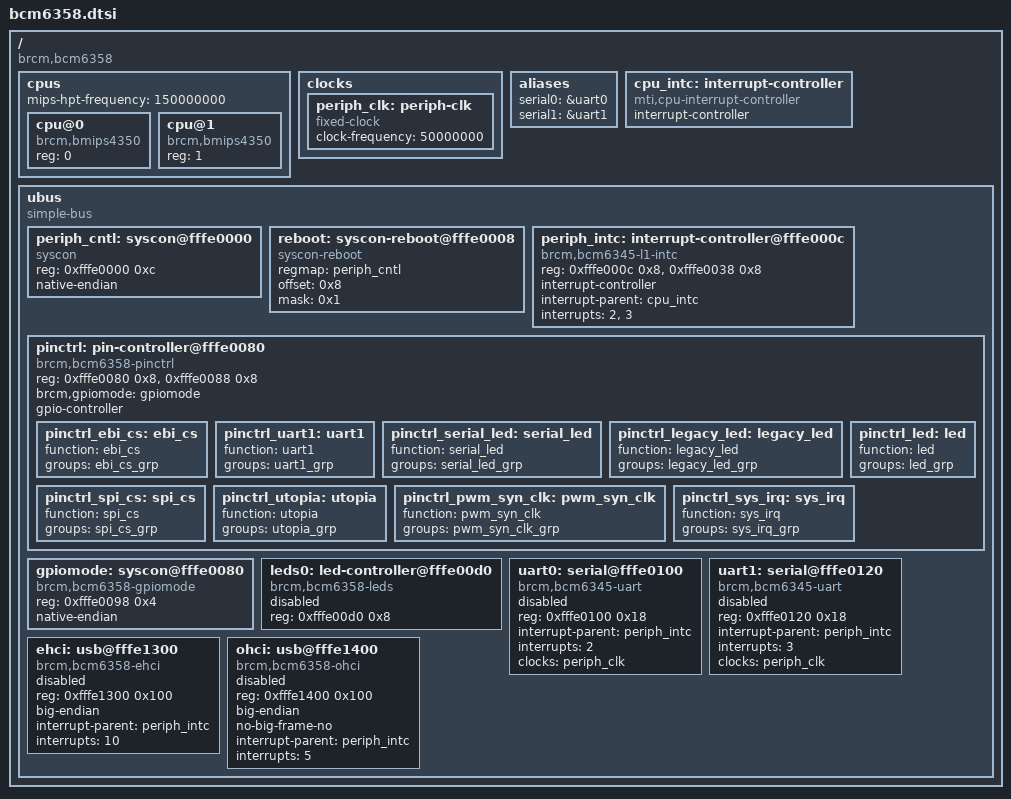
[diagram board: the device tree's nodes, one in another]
/ {
	#address-cells = <1>;
	#size-cells = <1>;
	compatible = "brcm,bcm6358";

	cpus {
		#address-cells = <1>;
		#size-cells = <0>;

		mips-hpt-frequency = <150000000>;

		cpu@0 {
			compatible = "brcm,bmips4350";
			device_type = "cpu";
			reg = <0>;
		};

		cpu@1 {
			compatible = "brcm,bmips4350";
			device_type = "cpu";
			reg = <1>;
		};
	};

	clocks {
		periph_clk: periph-clk {
			compatible = "fixed-clock";
			#clock-cells = <0>;
			clock-frequency = <50000000>;
		};
	};

	aliases {
		serial0 = &uart0;
		serial1 = &uart1;
	};

	cpu_intc: interrupt-controller {
		#address-cells = <0>;
		compatible = "mti,cpu-interrupt-controller";

		interrupt-controller;
		#interrupt-cells = <1>;
	};

	ubus {
		#address-cells = <1>;
		#size-cells = <1>;

		compatible = "simple-bus";
		ranges;

		periph_cntl: syscon@fffe0000 {
			compatible = "syscon";
			reg = <0xfffe0000 0xc>;
			native-endian;
		};

		reboot: syscon-reboot@fffe0008 {
			compatible = "syscon-reboot";
			regmap = <&periph_cntl>;
			offset = <0x8>;
			mask = <0x1>;
		};

		periph_intc: interrupt-controller@fffe000c {
			compatible = "brcm,bcm6345-l1-intc";
			reg = <0xfffe000c 0x8>,
			      <0xfffe0038 0x8>;

			interrupt-controller;
			#interrupt-cells = <1>;

			interrupt-parent = <&cpu_intc>;
			interrupts = <2>, <3>;
		};

		pinctrl: pin-controller@fffe0080 {
			compatible = "brcm,bcm6358-pinctrl";
			reg = <0xfffe0080 0x8>,
			      <0xfffe0088 0x8>;
			reg-names = "dirout", "dat";
			brcm,gpiomode = <&gpiomode>;

			gpio-controller;
			#gpio-cells = <2>;

			pinctrl_ebi_cs: ebi_cs {
				function = "ebi_cs";
				groups = "ebi_cs_grp";
			};

			pinctrl_uart1: uart1 {
				function = "uart1";
				groups = "uart1_grp";
			};

			pinctrl_serial_led: serial_led {
				function = "serial_led";
				groups = "serial_led_grp";
			};

			pinctrl_legacy_led: legacy_led {
				function = "legacy_led";
				groups = "legacy_led_grp";
			};

			pinctrl_led: led {
				function = "led";
				groups = "led_grp";
			};

			pinctrl_spi_cs: spi_cs {
				function = "spi_cs";
				groups = "spi_cs_grp";
			};

			pinctrl_utopia: utopia {
				function = "utopia";
				groups = "utopia_grp";
			};

			pinctrl_pwm_syn_clk: pwm_syn_clk {
				function = "pwm_syn_clk";
				groups = "pwm_syn_clk_grp";
			};

			pinctrl_sys_irq: sys_irq {
				function = "sys_irq";
				groups = "sys_irq_grp";
			};
		};

		gpiomode: syscon@fffe0080 {
			compatible = "brcm,bcm6358-gpiomode", "syscon";

			reg = <0xfffe0098 0x4>;
			native-endian;
		};

		leds0: led-controller@fffe00d0 {
			#address-cells = <1>;
			#size-cells = <0>;
			compatible = "brcm,bcm6358-leds";
			reg = <0xfffe00d0 0x8>;

			status = "disabled";
		};

		uart0: serial@fffe0100 {
			compatible = "brcm,bcm6345-uart";
			reg = <0xfffe0100 0x18>;

			interrupt-parent = <&periph_intc>;
			interrupts = <2>;

			clocks = <&periph_clk>;

			status = "disabled";
		};

		uart1: serial@fffe0120 {
			compatible = "brcm,bcm6345-uart";
			reg = <0xfffe0120 0x18>;

			interrupt-parent = <&periph_intc>;
			interrupts = <3>;

			clocks = <&periph_clk>;

			status = "disabled";
		};

		ehci: usb@fffe1300 {
			compatible = "brcm,bcm6358-ehci", "generic-ehci";
			reg = <0xfffe1300 0x100>;
			big-endian;
			interrupt-parent = <&periph_intc>;
			interrupts = <10>;
			status = "disabled";
		};

		ohci: usb@fffe1400 {
			compatible = "brcm,bcm6358-ohci", "generic-ohci";
			reg = <0xfffe1400 0x100>;
			big-endian;
			no-big-frame-no;
			interrupt-parent = <&periph_intc>;
			interrupts = <5>;
			status = "disabled";
		};
	};
};
